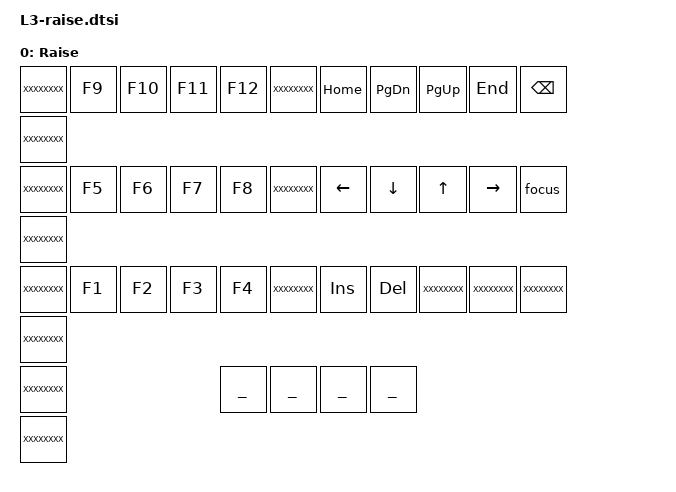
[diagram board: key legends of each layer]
/**
 *
 */

/ {
  keymap {
    compatible = "zmk,keymap";

	raise_layer {
		label = "Raise";
   		bindings = <
//					╭───────────────┬───────────────┬───────────────┬───────────────┬───────────────╮   ╭───────────────┬───────────────┬───────────────┬───────────────┬───────────────╮
	XXXXXXXX			&kp F9        	&kp F10        	&kp F11        	&kp F12        	XXXXXXXX			&kp HOME        &kp PG_DN		&kp PG_UP		&kp END			&kp BSPC
	XXXXXXXX	//	├───────────────┼───────────────┼───────────────┼───────────────┼───────────────┤   ├───────────────├───────────────┼───────────────┼───────────────┼───────────────┤
	XXXXXXXX			&kp F5        	&kp F6        	&kp F7        	&kp F8        	XXXXXXXX			&kp LEFT		&kp DOWN		&kp UP			&kp RIGHT		&focus
	XXXXXXXX	//	├───────────────┼───────────────┼───────────────┼───────────────┼───────────────┤   ├───────────────├───────────────┼───────────────┼───────────────┼───────────────┤
	XXXXXXXX			&kp F1        	&kp F2        	&kp F3        	&kp F4        	XXXXXXXX			&kp INS   		&kp DEL        XXXXXXXX        XXXXXXXX        XXXXXXXX
	XXXXXXXX	//	╰───────────────┴───────────────┼───────────────┼───────────────┼───────────────┤   ├───────────────├───────────────┼───────────────┼───────────────┴───────────────╯
	XXXXXXXX       														________		________			________		________
//                                                                  ╰───────────────┴───────────────╯   ╰───────────────┴───────────────╯
	XXXXXXXX
			>;
		};
	};
};
